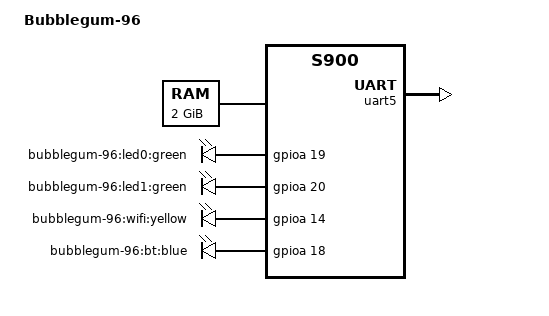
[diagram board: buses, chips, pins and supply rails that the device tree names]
/*
 * Copyright (c) 2017 Andreas Färber
 *
 * SPDX-License-Identifier: (GPL-2.0+ OR MIT)
 */

/dts-v1/;

#include <dt-bindings/gpio/gpio.h>

#include "s900.dtsi"

/ {
	compatible = "ucrobotics,bubblegum-96", "actions,s900";
	model = "Bubblegum-96";

	aliases {
		serial5 = &uart5;
	};

	chosen {
		stdout-path = "serial5:115200n8";
	};

	memory@0 {
		device_type = "memory";
		reg = <0x0 0x0 0x0 0x80000000>;
	};

	leds {
		compatible = "gpio-leds";

		led0 {
			label = "bubblegum-96:led0:green";
			gpios = <&gpioa 19 GPIO_ACTIVE_HIGH>;
			linux,default-trigger = "heartbeat";
		};

		led1 {
			label = "bubblegum-96:led1:green";
			gpios = <&gpioa 20 GPIO_ACTIVE_HIGH>;
			linux,default-trigger = "heartbeat";
		};

		/*led2 {
			label = "bubblegum-96:led2:green";
			gpios = <&gpiof 1 GPIO_ACTIVE_HIGH>;
			linux,default-trigger = "heartbeat";
		};

		led3 {
			label = "bubblegum-96:led3:green";
			gpios = <&gpiof 2 GPIO_ACTIVE_HIGH>;
			linux,default-trigger = "heartbeat";
		};*/

		wifi {
			label = "bubblegum-96:wifi:yellow";
			gpios = <&gpioa 14 GPIO_ACTIVE_HIGH>;
			linux,default-trigger = "heartbeat";
		};

		bt {
			label = "bubblegum-96:bt:blue";
			gpios = <&gpioa 18 GPIO_ACTIVE_HIGH>;
			linux,default-trigger = "heartbeat";
		};
	};

	uart5_clk: uart5-clk {
		compatible = "fixed-clock";
		clock-frequency = <921600>;
		#clock-cells = <0>;
	};
};

&timer {
	clocks = <&hosc>;
};

&uart5 {
	status = "okay";
	clocks = <&uart5_clk>;
};
